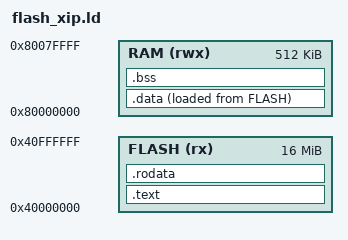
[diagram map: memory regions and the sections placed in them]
OUTPUT_ARCH("riscv")
ENTRY(_start)

MEMORY
{
    FLASH (rx)  : ORIGIN = 0x40000000, LENGTH = 16M
    RAM   (rwx) : ORIGIN = 0x80000000, LENGTH = 512K
}

SECTIONS
{
    .text : {
        KEEP(*(.text.entry))
        *(.text .text.*)
    } > FLASH

    .rodata : {
        . = ALIGN(4);
        *(.rodata .rodata.*)
        *(.srodata .srodata.*)
    } > FLASH

    .data : {
        . = ALIGN(4);
        __data_start = .;
        *(.data .data.*)
        *(.sdata .sdata.*)
        __data_end = .;
    } > RAM AT > FLASH

    .bss : {
        . = ALIGN(4);
        __bss_start = .;
        *(.bss .bss.*)
        *(.sbss .sbss.*)
        *(COMMON)
        __bss_end = .;
    } > RAM

    __stack_top = ORIGIN(RAM) + LENGTH(RAM);
}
